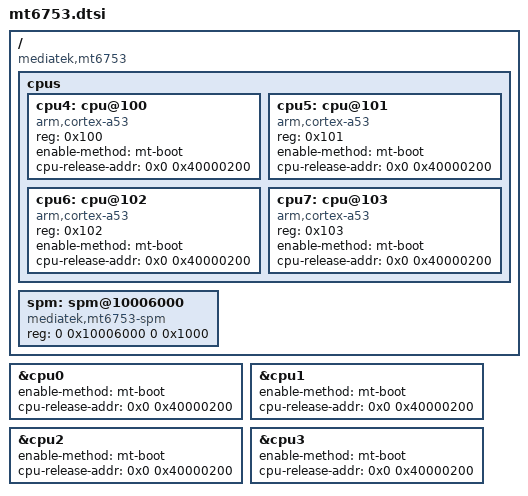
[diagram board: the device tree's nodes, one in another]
// SPDX-License-Identifier: BSD-3-Clause
/*
 * MediaTek MT6753
 *
 * MT6753 is the eight-core member of the MT6735 SoC family.  The vendor
 * 3.18 kernel uses a single "mt6735" platform for MT6735, MT6735M and
 * MT6753: arch/arm64/boot/dts/mt6753.dtsi in the downstream tree selects
 * mediatek,MT6735 as the root compatible and instantiates the clock,
 * pinctrl and pwrap controllers with the mt6735 compatibles.
 *
 * The only SoC-level difference described by the vendor DTS is the CPU
 * topology: four Cortex-A53 cores in cluster 0 (MPIDR 0x0..0x3) and four
 * in cluster 1 (MPIDR 0x100..0x103).
 */

#include "mt6735.dtsi"

/ {
	compatible = "mediatek,mt6753";

	cpus {
		cpu4: cpu@100 {
			device_type = "cpu";
			compatible = "arm,cortex-a53";
			reg = <0x100>;
			enable-method = "mt-boot";
			cpu-release-addr = <0x0 0x40000200>;
		};

		cpu5: cpu@101 {
			device_type = "cpu";
			compatible = "arm,cortex-a53";
			reg = <0x101>;
			enable-method = "mt-boot";
			cpu-release-addr = <0x0 0x40000200>;
		};

		cpu6: cpu@102 {
			device_type = "cpu";
			compatible = "arm,cortex-a53";
			reg = <0x102>;
			enable-method = "mt-boot";
			cpu-release-addr = <0x0 0x40000200>;
		};

		cpu7: cpu@103 {
			device_type = "cpu";
			compatible = "arm,cortex-a53";
			reg = <0x103>;
			enable-method = "mt-boot";
			cpu-release-addr = <0x0 0x40000200>;
		};
	};

	/*
	 * System Power Manager (SPM): CPU MTCMOS control for the "mt-boot"
	 * SMP method.  Same block and layout as the downstream "SLEEP" node
	 * (arch/arm64/boot/dts/mt6753.dtsi:318-325: compatible
	 * "mediatek,SLEEP", reg <0x10006000 0x1000>, no clocks; the SPM bus
	 * clock is enabled by the bootloader and there is no clock gate for
	 * it in the vendor DT).
	 */
	spm: spm@10006000 {
		compatible = "mediatek,mt6753-spm";
		reg = <0 0x10006000 0 0x1000>;
	};
};

/*
 * Cluster 0 is described in the shared mt6735.dtsi, which is also used by
 * the four-core MT6735/MT6737M boards that boot through plain PSCI.  The
 * downstream MT6753 DTS puts every core on "mt-boot" (PSCI CPU_ON + SPM
 * MTCMOS power-on), and the BSP assumes the preloader leaves all
 * non-boot cores powered off; the MT6735-family BL31 images we could
 * check do not touch the SPM block either.  cpu-release-addr is kept for
 * parity with the vendor DT
 * (arch/arm64/boot/dts/mt6753.dtsi:58-135); BL31 gets the real entrypoint
 * through the PSCI CPU_ON SMC call.
 */
&cpu0 {
	enable-method = "mt-boot";
	cpu-release-addr = <0x0 0x40000200>;
};

&cpu1 {
	enable-method = "mt-boot";
	cpu-release-addr = <0x0 0x40000200>;
};

&cpu2 {
	enable-method = "mt-boot";
	cpu-release-addr = <0x0 0x40000200>;
};

&cpu3 {
	enable-method = "mt-boot";
	cpu-release-addr = <0x0 0x40000200>;
};
